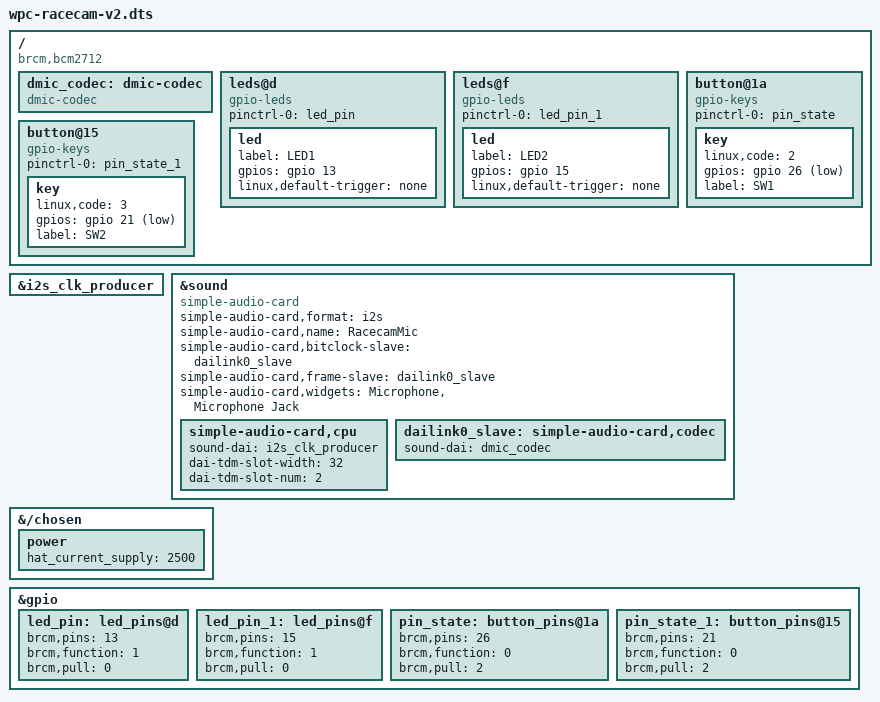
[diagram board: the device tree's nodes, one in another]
// redo: ovmerge -c wpc-racecam.dts gpio-led-overlay.dts,label=LED1,gpio=13 gpio-led-overlay.dts,label=LED2,gpio=15 gpio-key-overlay.dts,label=SW1,gpio=26,keycode=2 gpio-key-overlay.dts,label=SW2,gpio=21,keycode=3

/dts-v1/;
/plugin/;

/ {
	compatible = "brcm,bcm2712";
	fragment@0 {
		target = <&i2s_clk_producer>;
		__overlay__ {
			status = "okay";
		};
	};
	fragment@1 {
		target-path = "/";
		__overlay__ {
			dmic_codec: dmic-codec {
				#sound-dai-cells = <0>;
				compatible = "dmic-codec";
				status = "okay";
			};
		};
	};
	fragment@2 {
		target = <&sound>;
		sound_overlay: __overlay__ {
			compatible = "simple-audio-card";
			simple-audio-card,format = "i2s";
			simple-audio-card,name = "RacecamMic";
			simple-audio-card,bitclock-slave = <&dailink0_slave>;
			simple-audio-card,frame-slave = <&dailink0_slave>;
			simple-audio-card,widgets = "Microphone", "Microphone Jack";
			status = "okay";
			simple-audio-card,cpu {
				sound-dai = <&i2s_clk_producer>;
				dai-tdm-slot-width = <32>;
				dai-tdm-slot-num = <2>;
			};
			dailink0_slave: simple-audio-card,codec {
				#sound-dai-cells = <0>;
				sound-dai = <&dmic_codec>;
			};
		};
	};
	fragment@3 {
		target-path = "/chosen";
		__overlay__ {
			power: power {
				hat_current_supply = <2500>;
			};
		};
	};
	fragment@4 {
		target = <&gpio>;
		__overlay__ {
			led_pin: led_pins@d {
				brcm,pins = <13>;
				brcm,function = <1>;
				brcm,pull = <0>;
			};
		};
	};
	fragment@5 {
		target-path = "/";
		__overlay__ {
			leds@d {
				compatible = "gpio-leds";
				pinctrl-names = "default";
				pinctrl-0 = <&led_pin>;
				status = "okay";
				led {
					label = "LED1";
					gpios = <&gpio 13 0>;
					linux,default-trigger = "none";
				};
			};
		};
	};
	fragment@6 {
		target = <&gpio>;
		__overlay__ {
			led_pin_1: led_pins@f {
				brcm,pins = <15>;
				brcm,function = <1>;
				brcm,pull = <0>;
			};
		};
	};
	fragment@7 {
		target-path = "/";
		__overlay__ {
			leds@f {
				compatible = "gpio-leds";
				pinctrl-names = "default";
				pinctrl-0 = <&led_pin_1>;
				status = "okay";
				led {
					label = "LED2";
					gpios = <&gpio 15 0>;
					linux,default-trigger = "none";
				};
			};
		};
	};
	fragment@8 {
		target = <&gpio>;
		__overlay__ {
			pin_state: button_pins@1a {
				brcm,pins = <26>;
				brcm,function = <0>;
				brcm,pull = <2>;
			};
		};
	};
	fragment@9 {
		target-path = "/";
		__overlay__ {
			button@1a {
				compatible = "gpio-keys";
				pinctrl-names = "default";
				pinctrl-0 = <&pin_state>;
				status = "okay";
				key {
					linux,code = <2>;
					gpios = <&gpio 26 1>;
					label = "SW1";
				};
			};
		};
	};
	fragment@10 {
		target = <&gpio>;
		__overlay__ {
			pin_state_1: button_pins@15 {
				brcm,pins = <21>;
				brcm,function = <0>;
				brcm,pull = <2>;
			};
		};
	};
	fragment@11 {
		target-path = "/";
		__overlay__ {
			button@15 {
				compatible = "gpio-keys";
				pinctrl-names = "default";
				pinctrl-0 = <&pin_state_1>;
				status = "okay";
				key {
					linux,code = <3>;
					gpios = <&gpio 21 1>;
					label = "SW2";
				};
			};
		};
	};
	__overrides__ {
		card-name = <&sound_overlay>, "simple-audio-card,name";
		mode0 = <&power>, "hat_current_supply:0=3000";
		mode1 = <&power>, "hat_current_supply:0=5000";
	};
};
